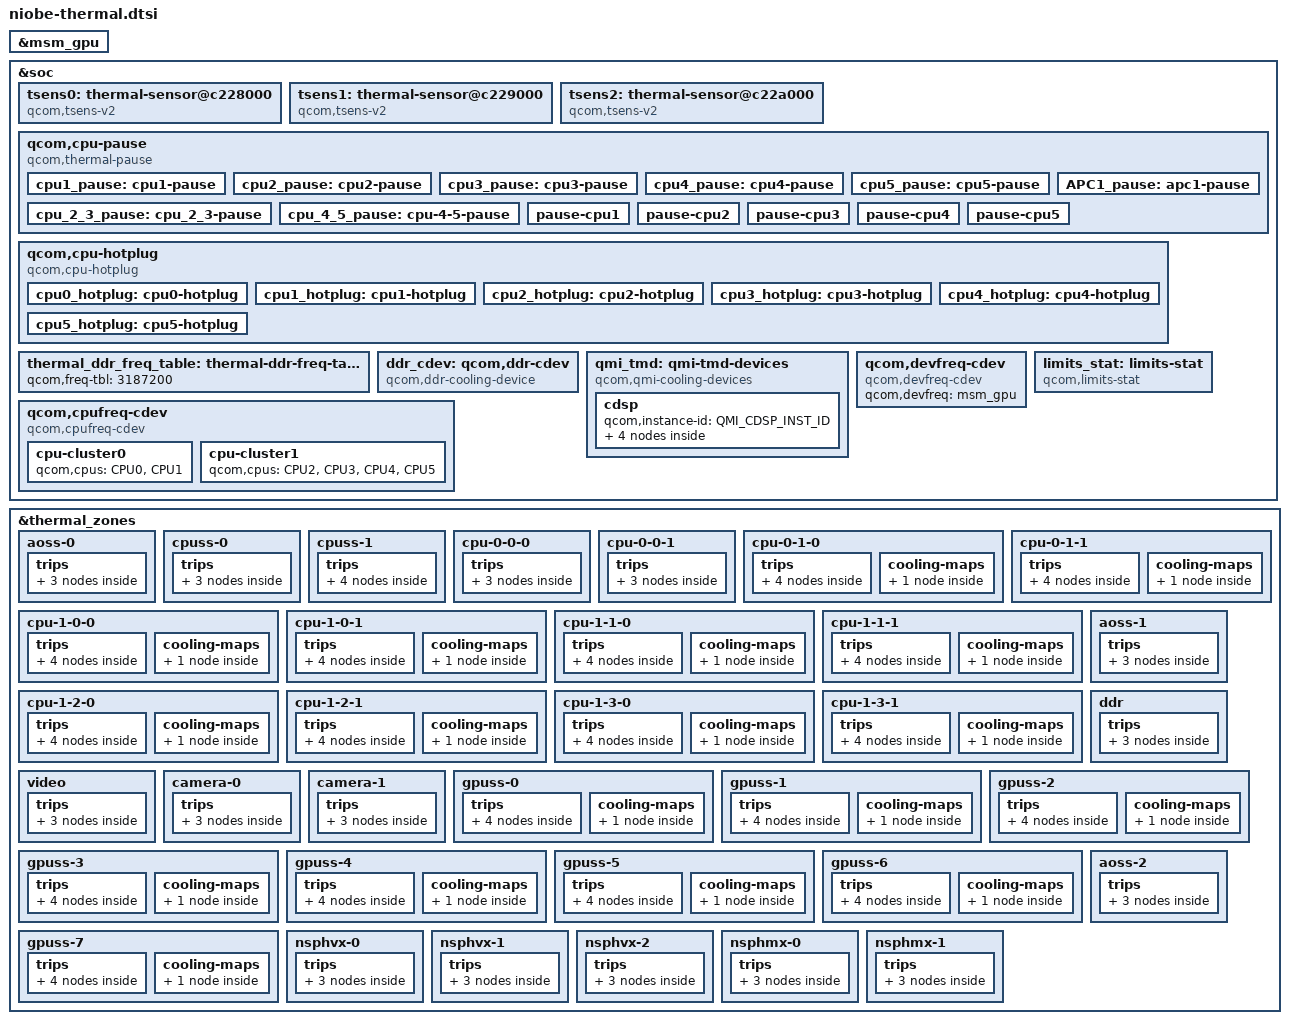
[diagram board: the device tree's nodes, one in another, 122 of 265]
#include <dt-bindings/thermal/thermal_qti.h>

&msm_gpu {
	#cooling-cells = <2>;
};

&soc {
	tsens0: thermal-sensor@c228000 {
		compatible = "qcom,tsens-v2";
		reg = <0x0c228000 0x1ff>, /* TM */
			<0x0c222000 0x1ff>; /* SROT */
		#qcom,sensors = <15>;
		interrupts = <GIC_SPI 376 IRQ_TYPE_LEVEL_HIGH>,
				<GIC_SPI 601 IRQ_TYPE_LEVEL_HIGH>;
		interrupt-names = "uplow",
				"critical";
		#thermal-sensor-cells = <1>;
	};

	tsens1: thermal-sensor@c229000 {
		compatible = "qcom,tsens-v2";
		reg = <0x0c229000 0x1ff>, /* TM */
			<0x0c223000 0x1ff>; /* SROT */
		#qcom,sensors = <13>;
		interrupts = <GIC_SPI 377 IRQ_TYPE_LEVEL_HIGH>,
				<GIC_SPI 602 IRQ_TYPE_LEVEL_HIGH>;
		interrupt-names = "uplow",
			"critical";
		#thermal-sensor-cells = <1>;
	};

	tsens2: thermal-sensor@c22a000 {
		compatible = "qcom,tsens-v2";
		reg = <0x0c22a000 0x1ff>, /* TM */
			<0x0c224000 0x1ff>; /* SROT */
		#qcom,sensors = <6>;
		interrupts = <GIC_SPI 443 IRQ_TYPE_LEVEL_HIGH>,
				<GIC_SPI 603 IRQ_TYPE_LEVEL_HIGH>;
		interrupt-names = "uplow",
			"critical";
		#thermal-sensor-cells = <1>;
	};

	qcom,cpu-pause {
		compatible = "qcom,thermal-pause";

		cpu1_pause: cpu1-pause {
			qcom,cpus = <&CPU1>;
			qcom,cdev-alias = "thermal-pause-2";
			#cooling-cells = <2>;
		};

		cpu2_pause: cpu2-pause {
			qcom,cpus = <&CPU2>;
			qcom,cdev-alias = "thermal-pause-4";
			#cooling-cells = <2>;
		};

		cpu3_pause: cpu3-pause {
			qcom,cpus = <&CPU3>;
			qcom,cdev-alias = "thermal-pause-8";
			#cooling-cells = <2>;
		};

		cpu4_pause: cpu4-pause {
			qcom,cpus = <&CPU4>;
			qcom,cdev-alias = "thermal-pause-10";
			#cooling-cells = <2>;
		};

		cpu5_pause: cpu5-pause {
			qcom,cpus = <&CPU5>;
			qcom,cdev-alias = "thermal-pause-20";
			#cooling-cells = <2>;
		};

		cpu_2_3_pause: cpu_2_3-pause {
			qcom,cpus = <&CPU2 &CPU3>;
			qcom,cdev-alias = "thermal-pause-C";
			#cooling-cells = <2>;
		};

		cpu_4_5_pause: cpu-4-5-pause {
			qcom,cpus = <&CPU4 &CPU5>;
			qcom,cdev-alias = "thermal-pause-30";
			#cooling-cells = <2>;
		};

		APC1_pause: apc1-pause {
			qcom,cpus = <&CPU2 &CPU3 &CPU4 &CPU5>;
			qcom,cdev-alias = "thermal-pause-3C";
			#cooling-cells = <2>;
		};

		/* Thermal-engine cooling devices */

		pause-cpu1 {
			qcom,cpus = <&CPU1>;
			qcom,cdev-alias = "pause-cpu1";
		};

		pause-cpu2 {
			qcom,cpus = <&CPU2>;
			qcom,cdev-alias = "pause-cpu2";
		};

		pause-cpu3 {
			qcom,cpus = <&CPU3>;
			qcom,cdev-alias = "pause-cpu3";
		};

		pause-cpu4 {
			qcom,cpus = <&CPU4>;
			qcom,cdev-alias = "pause-cpu4";
		};

		pause-cpu5 {
			qcom,cpus = <&CPU5>;
			qcom,cdev-alias = "pause-cpu5";
		};
	};

	qcom,cpu-hotplug {
		compatible = "qcom,cpu-hotplug";

		cpu0_hotplug: cpu0-hotplug {
			qcom,cpu = <&CPU0>;
			qcom,cdev-alias = "cpu-hotplug0";
			#cooling-cells = <2>;
		};

		cpu1_hotplug: cpu1-hotplug {
			qcom,cpu = <&CPU1>;
			qcom,cdev-alias = "cpu-hotplug1";
			#cooling-cells = <2>;
		};

		cpu2_hotplug: cpu2-hotplug {
			qcom,cpu = <&CPU2>;
			qcom,cdev-alias = "cpu-hotplug2";
			#cooling-cells = <2>;
		};

		cpu3_hotplug: cpu3-hotplug {
			qcom,cpu = <&CPU3>;
			qcom,cdev-alias = "cpu-hotplug3";
			#cooling-cells = <2>;
		};

		cpu4_hotplug: cpu4-hotplug {
			qcom,cpu = <&CPU4>;
			qcom,cdev-alias = "cpu-hotplug4";
			#cooling-cells = <2>;
		};

		cpu5_hotplug: cpu5-hotplug {
			qcom,cpu = <&CPU5>;
			qcom,cdev-alias = "cpu-hotplug5";
			#cooling-cells = <2>;
		};
	};

	thermal_ddr_freq_table: thermal-ddr-freq-table {
		qcom,freq-tbl = < 3187200 >;
	};


	ddr_cdev: qcom,ddr-cdev {
		compatible = "qcom,ddr-cooling-device";
		#cooling-cells = <2>;
		qcom,freq-table = <&thermal_ddr_freq_table>;
		qcom,bus-width = <4>;
		interconnects = <&mc_virt MASTER_LLCC &mc_virt SLAVE_EBI1>;
	};

	qmi_tmd: qmi-tmd-devices {
		compatible = "qcom,qmi-cooling-devices";
		cdsp {
			qcom,instance-id = <QMI_CDSP_INST_ID>;

			cdsp_sw: cdsp {
				qcom,qmi-dev-name = "cdsp_sw";
				#cooling-cells = <2>;
			};

			cdsp_sw_hvx: cdsp_sw_hvx {
				qcom,qmi-dev-name = "cdsp_sw_hvx";
				#cooling-cells = <2>;
			};

			cdsp_sw_hmx: cdsp_sw_hmx {
				qcom,qmi-dev-name = "cdsp_sw_hmx";
				#cooling-cells = <2>;
			};

			cdsp_hw: cdsp_hw {
				qcom,qmi-dev-name = "cdsp_hw";
				#cooling-cells = <2>;
			};
		};
	};

	qcom,cpufreq-cdev {
		compatible = "qcom,cpufreq-cdev";
		cpu-cluster0 {
			qcom,cpus = <&CPU0 &CPU1>;
		};

		cpu-cluster1 {
			qcom,cpus = <&CPU2 &CPU3 &CPU4 &CPU5>;
		};
	};

	qcom,devfreq-cdev {
		compatible = "qcom,devfreq-cdev";
		qcom,devfreq = <&msm_gpu>;
	};

	limits_stat: limits-stat {
		compatible = "qcom,limits-stat";
		qcom,limits-stat-sensor-names = "aoss-0", "cpuss-0", "cpuss-1",
						"cpu-0-0-0", "cpu-0-0-1", "cpu-0-1-0",
						"cpu-0-1-1", "cpu-1-0-0", "cpu-1-0-1",
						"cpu-1-1-0", "cpu-1-1-1", "cpu-1-2-0",
						"cpu-1-2-1", "cpu-1-3-0", "cpu-1-3-1",
						"aoss-1", "ddr", "video", "camera-0",
						"camera-1", "gpuss-0", "gpuss-1", "gpuss-2",
						"gpuss-3", "gpuss-4", "gpuss-5", "gpuss-6",
						"gpuss-7", "aoss-2", "nsphvx-0", "nsphvx-1",
						"nsphvx-2", "nsphmx-0", "nsphmx-1";
	};
};

&thermal_zones {
	aoss-0 {
		polling-delay-passive = <0>;
		polling-delay = <0>;
		thermal-sensors = <&tsens0 0>;
		trips {
			thermal-engine-config {
				temperature = <125000>;
				hysteresis = <1000>;
				type = "passive";
			};

			thermal-hal-config {
				temperature = <125000>;
				hysteresis = <1000>;
				type = "passive";
			};

			reset-mon-cfg {
				temperature = <115000>;
				hysteresis = <5000>;
				type = "passive";
			};
		};
	};

	cpuss-0 {
		polling-delay-passive = <0>;
		polling-delay = <0>;
		thermal-sensors = <&tsens0 1>;
		trips {
			thermal-engine-config {
				temperature = <125000>;
				hysteresis = <1000>;
				type = "passive";
			};

			thermal-hal-config {
				temperature = <125000>;
				hysteresis = <1000>;
				type = "passive";
			};

			reset-mon-cfg {
				temperature = <115000>;
				hysteresis = <5000>;
				type = "passive";
			};
		};
	};

	cpuss-1 {
		polling-delay-passive = <0>;
		polling-delay = <0>;
		thermal-sensors = <&tsens0 2>;
		trips {
			thermal-engine-config {
				temperature = <125000>;
				hysteresis = <1000>;
				type = "passive";
			};

			thermal-hal-config {
				temperature = <125000>;
				hysteresis = <1000>;
				type = "passive";
			};

			reset-mon-cfg {
				temperature = <115000>;
				hysteresis = <5000>;
				type = "passive";
			};

			cpu01_config: cpu01-config {
				temperature = <110000>;
				hysteresis = <10000>;
				type = "passive";
			};
		};
	};

	cpu-0-0-0 {
		polling-delay-passive = <0>;
		polling-delay = <0>;
		thermal-sensors = <&tsens0 3>;
		trips {
			thermal-engine-config {
				temperature = <125000>;
				hysteresis = <1000>;
				type = "passive";
			};

			thermal-hal-config {
				temperature = <125000>;
				hysteresis = <1000>;
				type = "passive";
			};

			reset-mon-cfg {
				temperature = <115000>;
				hysteresis = <5000>;
				type = "passive";
			};
		};
	};

	cpu-0-0-1 {
		polling-delay-passive = <0>;
		polling-delay = <0>;
		thermal-sensors = <&tsens0 4>;
		trips {
			thermal-engine-config {
				temperature = <125000>;
				hysteresis = <1000>;
				type = "passive";
			};

			thermal-hal-config {
				temperature = <125000>;
				hysteresis = <1000>;
				type = "passive";
			};

			reset-mon-cfg {
				temperature = <115000>;
				hysteresis = <5000>;
				type = "passive";
			};
		};
	};

	cpu-0-1-0 {
		polling-delay-passive = <10>;
		polling-delay = <0>;
		thermal-sensors = <&tsens0 5>;
		trips {
			thermal-engine-config {
				temperature = <125000>;
				hysteresis = <1000>;
				type = "passive";
			};

			thermal-hal-config {
				temperature = <125000>;
				hysteresis = <1000>;
				type = "passive";
			};

			reset-mon-cfg {
				temperature = <115000>;
				hysteresis = <5000>;
				type = "passive";
			};

			cpu010_config: cpu010-config {
				temperature = <110000>;
				hysteresis = <10000>;
				type = "passive";
			};
		};

		cooling-maps {
			cpu010_cdev {
				trip = <&cpu010_config>;
				cooling-device = <&cpu1_pause 1 1>;
			};
		};
	};

	cpu-0-1-1 {
		polling-delay-passive = <10>;
		polling-delay = <0>;
		thermal-sensors = <&tsens0 6>;
		trips {
			thermal-engine-config {
				temperature = <125000>;
				hysteresis = <1000>;
				type = "passive";
			};

			thermal-hal-config {
				temperature = <125000>;
				hysteresis = <1000>;
				type = "passive";
			};

			reset-mon-cfg {
				temperature = <115000>;
				hysteresis = <5000>;
				type = "passive";
			};

			cpu011_config: cpu011-config {
				temperature = <110000>;
				hysteresis = <10000>;
				type = "passive";
			};
		};

		cooling-maps {
			cpu011_cdev {
				trip = <&cpu011_config>;
				cooling-device = <&cpu1_pause 1 1>;
			};
		};
	};

	cpu-1-0-0 {
		polling-delay-passive = <10>;
		polling-delay = <0>;
		thermal-sensors = <&tsens0 7>;
		trips {
			thermal-engine-config {
				temperature = <125000>;
				hysteresis = <1000>;
				type = "passive";
			};

			thermal-hal-config {
				temperature = <125000>;
				hysteresis = <1000>;
				type = "passive";
			};

			reset-mon-cfg {
				temperature = <115000>;
				hysteresis = <5000>;
				type = "passive";
			};

			cpu100_config: cpu100-config {
				temperature = <110000>;
				hysteresis = <10000>;
				type = "passive";
			};
		};

		cooling-maps {
			cpu100_cdev {
				trip = <&cpu100_config>;
				cooling-device = <&cpu2_pause 1 1>;
			};
		};
	};

	cpu-1-0-1 {
		polling-delay-passive = <10>;
		polling-delay = <0>;
		thermal-sensors = <&tsens0 8>;
		trips {
			thermal-engine-config {
				temperature = <125000>;
				hysteresis = <1000>;
				type = "passive";
			};

			thermal-hal-config {
				temperature = <125000>;
				hysteresis = <1000>;
				type = "passive";
			};

			reset-mon-cfg {
				temperature = <115000>;
				hysteresis = <5000>;
				type = "passive";
			};

			cpu101_config: cpu101-config {
				temperature = <110000>;
				hysteresis = <10000>;
				type = "passive";
			};
		};

		cooling-maps {
			cpu101_cdev {
				trip = <&cpu101_config>;
				cooling-device = <&cpu2_pause 1 1>;
			};
		};
	};

	cpu-1-1-0 {
		polling-delay-passive = <10>;
		polling-delay = <0>;
		thermal-sensors = <&tsens0 9>;
		trips {
			thermal-engine-config {
				temperature = <125000>;
				hysteresis = <1000>;
				type = "passive";
			};

			thermal-hal-config {
				temperature = <125000>;
				hysteresis = <1000>;
				type = "passive";
			};

			reset-mon-cfg {
				temperature = <115000>;
				hysteresis = <5000>;
				type = "passive";
			};

			cpu110_config: cpu110-config {
				temperature = <110000>;
				hysteresis = <10000>;
				type = "passive";
			};
		};

		cooling-maps {
			cpu110_cdev {
				trip = <&cpu110_config>;
				cooling-device = <&cpu3_pause 1 1>;
			};
		};
	};

	cpu-1-1-1 {
		polling-delay-passive = <10>;
		polling-delay = <0>;
		thermal-sensors = <&tsens0 10>;
		trips {
			thermal-engine-config {
				temperature = <125000>;
				hysteresis = <1000>;
				type = "passive";
			};

			thermal-hal-config {
				temperature = <125000>;
				hysteresis = <1000>;
				type = "passive";
			};

			reset-mon-cfg {
				temperature = <115000>;
				hysteresis = <5000>;
				type = "passive";
			};

			cpu111_config: cpu111-config {
				temperature = <110000>;
				hysteresis = <10000>;
				type = "passive";
			};
		};

		cooling-maps {
			cpu111_cdev {
				trip = <&cpu111_config>;
				cooling-device = <&cpu3_pause 1 1>;
			};
		};
	};

	cpu-1-2-0 {
		polling-delay-passive = <10>;
		polling-delay = <0>;
		thermal-sensors = <&tsens0 11>;
		trips {
			thermal-engine-config {
				temperature = <125000>;
				hysteresis = <1000>;
				type = "passive";
			};

			thermal-hal-config {
				temperature = <125000>;
				hysteresis = <1000>;
				type = "passive";
			};

			reset-mon-cfg {
				temperature = <115000>;
				hysteresis = <5000>;
				type = "passive";
			};

			cpu120_config: cpu120-config {
				temperature = <110000>;
				hysteresis = <10000>;
				type = "passive";
			};
		};

		cooling-maps {
			cpu120_cdev {
				trip = <&cpu120_config>;
				cooling-device = <&cpu4_pause 1 1>;
			};
		};
	};

	cpu-1-2-1 {
		polling-delay-passive = <10>;
		polling-delay = <0>;
		thermal-sensors = <&tsens0 12>;
		trips {
			thermal-engine-config {
				temperature = <125000>;
				hysteresis = <1000>;
				type = "passive";
			};

			thermal-hal-config {
				temperature = <125000>;
				hysteresis = <1000>;
				type = "passive";
			};

			reset-mon-cfg {
				temperature = <115000>;
				hysteresis = <5000>;
				type = "passive";
			};

			cpu121_config: cpu121-config {
				temperature = <110000>;
				hysteresis = <10000>;
				type = "passive";
			};
		};

		cooling-maps {
			cpu121_cdev {
				trip = <&cpu121_config>;
				cooling-device = <&cpu4_pause 1 1>;
			};
		};
	};

	cpu-1-3-0 {
		polling-delay-passive = <10>;
		polling-delay = <0>;
		thermal-sensors = <&tsens0 13>;
		trips {
			thermal-engine-config {
				temperature = <125000>;
				hysteresis = <1000>;
				type = "passive";
			};

			thermal-hal-config {
				temperature = <125000>;
				hysteresis = <1000>;
				type = "passive";
			};

			reset-mon-cfg {
				temperature = <115000>;
				hysteresis = <5000>;
				type = "passive";
			};

			cpu130_config: cpu130-config {
				temperature = <110000>;
				hysteresis = <10000>;
				type = "passive";
			};
		};

		cooling-maps {
			cpu130_cdev {
				trip = <&cpu130_config>;
				cooling-device = <&cpu5_pause 1 1>;
			};
		};
	};

	cpu-1-3-1 {
		polling-delay-passive = <10>;
		polling-delay = <0>;
		thermal-sensors = <&tsens0 14>;
		trips {
			thermal-engine-config {
				temperature = <125000>;
				hysteresis = <1000>;
				type = "passive";
			};

			thermal-hal-config {
				temperature = <125000>;
				hysteresis = <1000>;
				type = "passive";
			};

			reset-mon-cfg {
				temperature = <115000>;
				hysteresis = <5000>;
				type = "passive";
			};

			cpu131_config: cpu131-config {
				temperature = <110000>;
				hysteresis = <10000>;
				type = "passive";
			};
		};

		cooling-maps {
			cpu131_cdev {
				trip = <&cpu131_config>;
				cooling-device = <&cpu5_pause 1 1>;
			};
		};
	};

	aoss-1 {
		polling-delay-passive = <0>;
		polling-delay = <0>;
		thermal-sensors = <&tsens1 0>;
		trips {
			thermal-engine-config {
				temperature = <125000>;
				hysteresis = <1000>;
				type = "passive";
			};

			thermal-hal-config {
				temperature = <125000>;
				hysteresis = <1000>;
				type = "passive";
			};

			reset-mon-cfg {
				temperature = <115000>;
				hysteresis = <5000>;
				type = "passive";
			};
		};
	};

	ddr {
		polling-delay-passive = <10>;
		polling-delay = <0>;
		thermal-sensors = <&tsens1 1>;
		trips {
			thermal-engine-config {
				temperature = <125000>;
				hysteresis = <1000>;
				type = "passive";
			};

			thermal-hal-config {
				temperature = <125000>;
				hysteresis = <1000>;
				type = "passive";
			};

			reset-mon-cfg {
				temperature = <115000>;
				hysteresis = <5000>;
				type = "passive";
			};
		};
	};

	video {
		polling-delay-passive = <0>;
		polling-delay = <0>;
		thermal-sensors = <&tsens1 2>;
		trips {
			thermal-engine-config {
				temperature = <125000>;
				hysteresis = <1000>;
				type = "passive";
			};

			thermal-hal-config {
				temperature = <125000>;
				hysteresis = <1000>;
				type = "passive";
			};

			reset-mon-cfg {
				temperature = <115000>;
				hysteresis = <5000>;
				type = "passive";
			};
		};
	};

	camera-0 {
		polling-delay-passive = <0>;
		polling-delay = <0>;
		thermal-sensors = <&tsens1 3>;
		trips {
			thermal-engine-config {
				temperature = <125000>;
				hysteresis = <1000>;
				type = "passive";
			};

			thermal-hal-config {
				temperature = <125000>;
				hysteresis = <1000>;
				type = "passive";
			};

			reset-mon-cfg {
				temperature = <115000>;
				hysteresis = <5000>;
				type = "passive";
			};
		};
	};

	camera-1 {
		polling-delay-passive = <0>;
		polling-delay = <0>;
		thermal-sensors = <&tsens1 4>;
		trips {
			thermal-engine-config {
				temperature = <125000>;
				hysteresis = <1000>;
				type = "passive";
			};

			thermal-hal-config {
				temperature = <125000>;
				hysteresis = <1000>;
				type = "passive";
			};

			reset-mon-cfg {
				temperature = <115000>;
				hysteresis = <5000>;
				type = "passive";
			};
		};
	};

	gpuss-0 {
		polling-delay-passive = <10>;
		polling-delay = <0>;
		thermal-sensors = <&tsens1 5>;
		trips {
			thermal-engine-config {
				temperature = <125000>;
				hysteresis = <1000>;
				type = "passive";
			};

			thermal-hal-config {
				temperature = <125000>;
				hysteresis = <1000>;
				type = "passive";
			};

			gpu0_tj_cfg: tj_cfg {
				temperature = <95000>;
				hysteresis = <5000>;
				type = "passive";
			};

			reset-mon-cfg {
				temperature = <115000>;
				hysteresis = <5000>;
				type = "passive";
			};
		};

		cooling-maps {
			gpu0_cdev {
				trip = <&gpu0_tj_cfg>;
				cooling-device = <&msm_gpu 0 THERMAL_NO_LIMIT>;
			};
		};
	};

	gpuss-1 {
		polling-delay-passive = <10>;
		polling-delay = <0>;
		thermal-sensors = <&tsens1 6>;
		trips {
			thermal-engine-config {
				temperature = <125000>;
				hysteresis = <1000>;
				type = "passive";
			};

			thermal-hal-config {
				temperature = <125000>;
				hysteresis = <1000>;
				type = "passive";
			};

			gpu1_tj_cfg: tj_cfg {
				temperature = <95000>;
				hysteresis = <5000>;
				type = "passive";
			};

			reset-mon-cfg {
				temperature = <115000>;
				hysteresis = <5000>;
				type = "passive";
			};
		};

		cooling-maps {
			gpu1_cdev {
				trip = <&gpu1_tj_cfg>;
				cooling-device = <&msm_gpu 0 THERMAL_NO_LIMIT>;
			};
		};
	};

	gpuss-2 {
		polling-delay-passive = <10>;
		polling-delay = <0>;
		thermal-sensors = <&tsens1 7>;
		trips {
			thermal-engine-config {
				temperature = <125000>;
				hysteresis = <1000>;
				type = "passive";
			};

			thermal-hal-config {
				temperature = <125000>;
				hysteresis = <1000>;
				type = "passive";
			};

			gpu2_tj_cfg: tj_cfg {
				temperature = <95000>;
				hysteresis = <5000>;
				type = "passive";
			};

			reset-mon-cfg {
				temperature = <115000>;
				hysteresis = <5000>;
				type = "passive";
			};
		};

		cooling-maps {
			gpu2_cdev {
				trip = <&gpu2_tj_cfg>;
				cooling-device = <&msm_gpu 0 THERMAL_NO_LIMIT>;
			};
		};
	};

	gpuss-3 {
		polling-delay-passive = <10>;
		polling-delay = <0>;
		thermal-sensors = <&tsens1 8>;
		trips {
			thermal-engine-config {
				temperature = <125000>;
				hysteresis = <1000>;
				type = "passive";
			};

			thermal-hal-config {
				temperature = <125000>;
				hysteresis = <1000>;
				type = "passive";
			};

			gpu3_tj_cfg: tj_cfg {
				temperature = <95000>;
				hysteresis = <5000>;
				type = "passive";
			};

			reset-mon-cfg {
				temperature = <115000>;
				hysteresis = <5000>;
				type = "passive";
			};
		};

		cooling-maps {
			gpu3_cdev {
				trip = <&gpu3_tj_cfg>;
				cooling-device = <&msm_gpu 0 THERMAL_NO_LIMIT>;
			};
		};
	};

	gpuss-4 {
		polling-delay-passive = <10>;
		polling-delay = <0>;
		thermal-sensors = <&tsens1 9>;
		trips {
			thermal-engine-config {
				temperature = <125000>;
				hysteresis = <1000>;
				type = "passive";
			};

			thermal-hal-config {
				temperature = <125000>;
				hysteresis = <1000>;
				type = "passive";
			};

			gpu4_tj_cfg: tj_cfg {
				temperature = <95000>;
				hysteresis = <5000>;
				type = "passive";
			};

			reset-mon-cfg {
				temperature = <115000>;
				hysteresis = <5000>;
				type = "passive";
			};
		};

		cooling-maps {
			gpu4_cdev {
				trip = <&gpu4_tj_cfg>;
				cooling-device = <&msm_gpu 0 THERMAL_NO_LIMIT>;
			};
		};
	};

	gpuss-5 {
		polling-delay-passive = <10>;
		polling-delay = <0>;
		thermal-sensors = <&tsens1 10>;
		trips {
			thermal-engine-config {
				temperature = <125000>;
				hysteresis = <1000>;
				type = "passive";
			};

			thermal-hal-config {
				temperature = <125000>;
				hysteresis = <1000>;
				type = "passive";
			};

			gpu5_tj_cfg: tj_cfg {
				temperature = <95000>;
				hysteresis = <5000>;
				type = "passive";
			};

			reset-mon-cfg {
				temperature = <115000>;
				hysteresis = <5000>;
				type = "passive";
			};
		};

		cooling-maps {
			gpu5_cdev {
				trip = <&gpu5_tj_cfg>;
				cooling-device = <&msm_gpu 0 THERMAL_NO_LIMIT>;
			};
		};
	};

	gpuss-6 {
		polling-delay-passive = <10>;
		polling-delay = <0>;
		thermal-sensors = <&tsens1 11>;
		trips {
			thermal-engine-config {
				temperature = <125000>;
				hysteresis = <1000>;
				type = "passive";
			};

			thermal-hal-config {
				temperature = <125000>;
				hysteresis = <1000>;
				type = "passive";
			};

			gpu6_tj_cfg: tj_cfg {
				temperature = <95000>;
				hysteresis = <5000>;
				type = "passive";
			};

			reset-mon-cfg {
				temperature = <115000>;
				hysteresis = <5000>;
				type = "passive";
			};
		};

		cooling-maps {
			gpu6_cdev {
				trip = <&gpu6_tj_cfg>;
				cooling-device = <&msm_gpu 0 THERMAL_NO_LIMIT>;
			};
		};
	};

	gpuss-7 {
		polling-delay-passive = <10>;
		polling-delay = <0>;
		thermal-sensors = <&tsens1 12>;
		trips {
			thermal-engine-config {
				temperature = <125000>;
				hysteresis = <1000>;
				type = "passive";
			};

			thermal-hal-config {
				temperature = <125000>;
				hysteresis = <1000>;
				type = "passive";
			};

			gpu7_tj_cfg: tj_cfg {
				temperature = <95000>;
				hysteresis = <5000>;
				type = "passive";
			};

			reset-mon-cfg {
				temperature = <115000>;
				hysteresis = <5000>;
				type = "passive";
			};
		};

		cooling-maps {
			gpu7_cdev {
				trip = <&gpu7_tj_cfg>;
				cooling-device = <&msm_gpu 0 THERMAL_NO_LIMIT>;
			};
		};
	};

	aoss-2 {
		polling-delay-passive = <0>;
		polling-delay = <0>;
		thermal-sensors = <&tsens2 0>;
		trips {
			thermal-engine-config {
				temperature = <125000>;
				hysteresis = <1000>;
				type = "passive";
			};

			thermal-hal-config {
				temperature = <125000>;
				hysteresis = <1000>;
				type = "passive";
			};

			reset-mon-cfg {
				temperature = <115000>;
				hysteresis = <5000>;
				type = "passive";
			};
		};
	};

	nsphvx-0 {
		polling-delay-passive = <0>;
		polling-delay = <0>;
		thermal-sensors = <&tsens2 1>;
		trips {
			thermal-engine-config {
				temperature = <125000>;
				hysteresis = <1000>;
				type = "passive";
			};

			thermal-hal-config {
				temperature = <125000>;
				hysteresis = <1000>;
				type = "passive";
			};

			reset-mon-cfg {
				temperature = <115000>;
				hysteresis = <5000>;
				type = "passive";
			};
		};
	};

	nsphvx-1 {
		polling-delay-passive = <0>;
		polling-delay = <0>;
		thermal-sensors = <&tsens2 2>;
		trips {
			thermal-engine-config {
				temperature = <125000>;
				hysteresis = <1000>;
				type = "passive";
			};

			thermal-hal-config {
				temperature = <125000>;
				hysteresis = <1000>;
				type = "passive";
			};

			reset-mon-cfg {
				temperature = <115000>;
				hysteresis = <5000>;
				type = "passive";
			};
		};
	};

	nsphvx-2 {
		polling-delay-passive = <0>;
		polling-delay = <0>;
		thermal-sensors = <&tsens2 3>;
		trips {
			thermal-engine-config {
				temperature = <125000>;
				hysteresis = <1000>;
				type = "passive";
			};

			thermal-hal-config {
				temperature = <125000>;
				hysteresis = <1000>;
				type = "passive";
			};

			reset-mon-cfg {
				temperature = <115000>;
				hysteresis = <5000>;
				type = "passive";
			};
		};
	};

	nsphmx-0 {
		polling-delay-passive = <0>;
		polling-delay = <0>;
		thermal-sensors = <&tsens2 4>;
		trips {
			thermal-engine-config {
				temperature = <125000>;
				hysteresis = <1000>;
				type = "passive";
			};

			thermal-hal-config {
				temperature = <125000>;
				hysteresis = <1000>;
				type = "passive";
			};

			reset-mon-cfg {
				temperature = <115000>;
				hysteresis = <5000>;
				type = "passive";
			};
		};
	};

	nsphmx-1 {
		polling-delay-passive = <0>;
		polling-delay = <0>;
		thermal-sensors = <&tsens2 5>;
		trips {
			thermal-engine-config {
				temperature = <125000>;
				hysteresis = <1000>;
				type = "passive";
			};

			thermal-hal-config {
				temperature = <125000>;
				hysteresis = <1000>;
				type = "passive";
			};

			reset-mon-cfg {
				temperature = <115000>;
				hysteresis = <5000>;
				type = "passive";
			};
		};
	};
};
